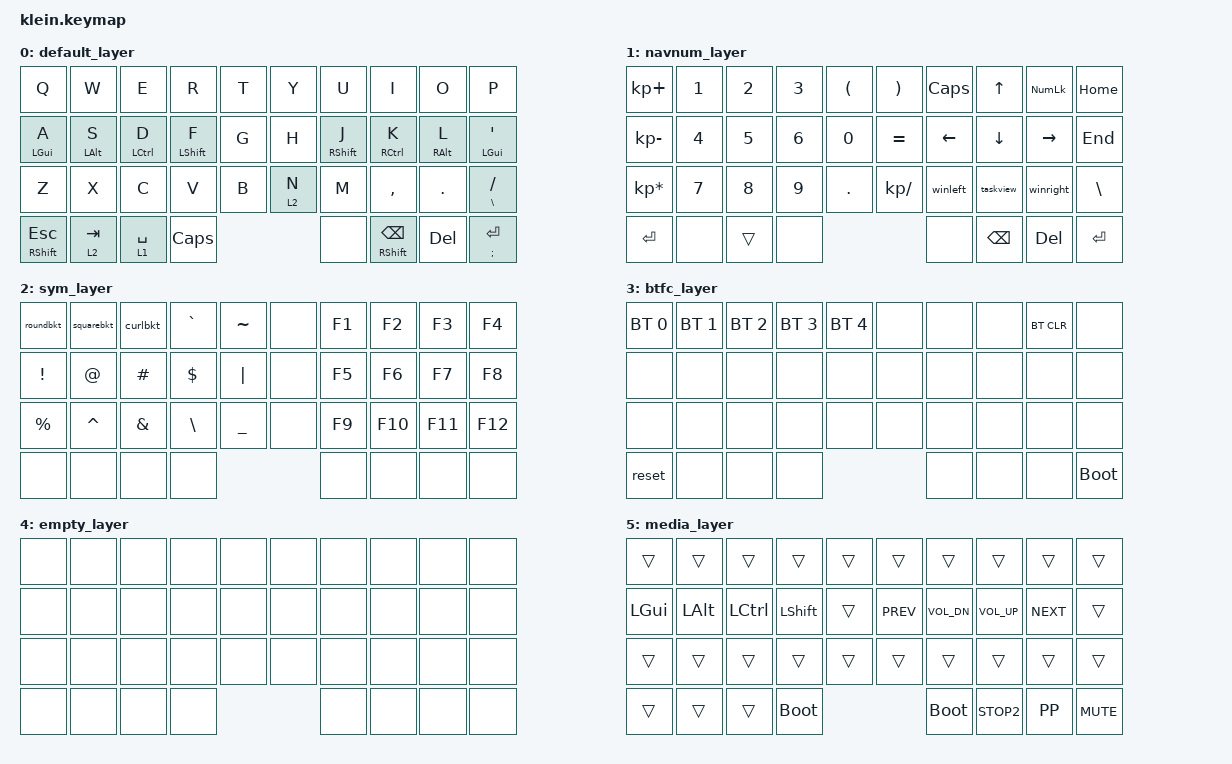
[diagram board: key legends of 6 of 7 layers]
/*
 * Copyright (c) 2020 The ZMK Contributors
 *
 * SPDX-License-Identifier: MIT
 */

#define ZMK_POINTING_DEFAULT_MOVE_VAL 1500  // default: 600
#define ZMK_POINTING_DEFAULT_SCRL_VAL 20    // default: 10
#define BASE 0
#define NAV  1
#define SYM  2
#define BTC  3
#define NON  4
#define MEDIA  5
#define BLU 6

#include <behaviors.dtsi> 
#include <dt-bindings/zmk/keys.h>
#include <dt-bindings/zmk/bt.h>
#include <dt-bindings/zmk/outputs.h>
#include <dt-bindings/zmk/pointing.h>


/ {

behaviors {

      macros {
         roundbkt: round_brackets {
            label= "round_brackets";
            compatible = "zmk,behavior-macro";
            #binding-cells = <0>; 
            bindings
                = <&macro_tap &kp LPAR &kp RPAR>;
         };
         
         
         squarebkt: square_brackets {
            label= "square_brackets";
            compatible = "zmk,behavior-macro";
            #binding-cells = <0>;
            bindings
                = <&macro_tap &kp LBKT &kp RBKT>;
         };
         
         
         curlbkt: curl_brackets {
            label= "curl_brackets";
            compatible = "zmk,behavior-macro";
            #binding-cells = <0>;
            bindings
                = <&macro_tap &kp LBRC &kp RBRC>;
         };
        
         apostrophe: apostrophe {
            label= "apostrophe";
            compatible = "zmk,behavior-macro";
            #binding-cells = <0>;
            bindings
                = <&macro_tap &kp DQT &kp DQT>;
         };
        
         winleft: winleft {
            label= "winleft";
            compatible = "zmk,behavior-macro";
            #binding-cells = <0>;
            bindings
                = <&macro_press &kp LGUI &kp LCTRL>, 
                <&macro_tap &kp LEFT>,
                <&macro_release &kp LGUI &kp LCTRL>;
         };
        
         winright: winright {
            label= "winright";
            compatible = "zmk,behavior-macro";
            #binding-cells = <0>;
            bindings
                = <&macro_press &kp LGUI &kp LCTRL>, 
                <&macro_tap &kp RIGHT>,
                <&macro_release &kp LGUI &kp LCTRL>;
         };
        
         taskview: taskview {
            label= "taskview";
            compatible = "zmk,behavior-macro";
            #binding-cells = <0>;
            bindings
                = <&macro_press &kp LGUI>, 
                <&macro_tap &kp TAB>,
                <&macro_release &kp LGUI>;
         };
      };
    
      hm: homerow_mods {
        compatible = "zmk,behavior-hold-tap";
        label = "HOMEROW_MODS";
        #binding-cells = <2>;
        tapping_term_ms = <150>;
        flavor = "tap-preferred";
        bindings = <&kp>, <&kp>;
    };
    
      te: tab_enter {
        compatible = "zmk,behavior-hold-tap";
        label = "TAB_ENTER";
        #binding-cells = <2>;
        tapping_term_ms = <50>;
        flavor = "tap-preferred";
        bindings = <&kp>, <&kp>;
    };
    
    td_mt_enter_tab_f2_f4: tap_dance_mod_tap_tab_esc {
            compatible = "zmk,behavior-tap-dance";
            label = "TAP_DANCE_MOD_TAP_enter_tab_f2_f4";
            #binding-cells = <0>;
            tapping-term-ms = <200>;
            bindings = <&te TAB ENTER>, <&kp F2>, <&kp F4>;
        };

    combos {
    compatible = "zmk,combos";
    combo_layer3 {
            timeout-ms = <50>;
            key-positions = <32 35>;
            bindings = <&mo 3>;
       };
    };
  };
};

/ {
    keymap {
        compatible = "zmk,keymap";

        default_layer {
//          ------------------------------------------------------------------------------------------------------------
//          |  Q  |  W  |  E   |  R       |  T   |                                           |  Y   |  U    |  I    |  O   |   P   |
//          |  A  |  S  |  D   |  F       |  G   |                                           |  H   |  J    |  K    |  L   |   '   |
//          |  Z  |  X  |  C   |  V       |  B   |                                           |  N   |  M    |  ,    |  .   |   /   |
//                      | ESC  | lyr2/TAB |  TAB | BOOTLOADER |                         | MUTE | RET | BKSP | DEL |

            bindings = <
&kp Q          &kp W          &kp E          &kp R          &kp T               &kp Y          &kp U          &kp I          &kp O          &kp P
&hm LGUI A     &hm LALT S     &hm LCTRL D    &hm LSHFT F    &kp G               &kp H          &hm RSHFT J    &hm RCTRL K    &hm RALT L     &hm LGUI SQT
&kp Z          &kp X          &kp C          &kp V          &kp B               &lt 2 N        &kp M          &kp COMMA      &kp DOT        &hm BSLH FSLH
&hm RSHFT ESC  &lt 2 TAB      &lt 1 SPACE    &kp CAPS                                          &none          &hm RSHFT BSPC &kp DEL        &hm SEMI ENTER
            >;
        sensor-bindings = <&inc_dec_msc SCRL_UP SCRL_DOWN &inc_dec_msc SCRL_LEFT SCRL_RIGHT>;
        };

        navnum_layer {

            bindings = <
&kp KP_PLUS     &kp N1         &kp N2         &kp N3         &kp LPAR            &kp RPAR       &kp CAPS       &kp UP         &kp KP_NUMLOCK &kp HOME
&kp KP_MINUS    &kp N4         &kp N5         &kp N6         &kp N0              &kp EQUAL      &kp LEFT       &kp DOWN       &kp RIGHT      &kp END
&kp KP_MULTIPLY &kp N7         &kp N8         &kp N9         &kp DOT             &kp KP_DIVIDE  &winleft       &taskview      &winright      &kp BSLH
&kp ENTER       &none          &trans         &none                                             &none          &kp BSPC       &kp DEL        &kp ENTER
            >;
        sensor-bindings = <&inc_dec_kp PG_UP PG_DN &inc_dec_kp HOME END>;
        };

        sym_layer {
            
            bindings = <
&roundbkt      &squarebkt     &curlbkt       &kp GRAVE      &kp TILDE           &none          &kp F1         &kp F2         &kp F3         &kp F4
&kp EXCL       &kp AT         &kp HASH       &kp DOLLAR     &kp PIPE            &none          &kp F5         &kp F6         &kp F7         &kp F8
&kp PRCNT      &kp CARET      &kp AMPERSAND  &kp BACKSLASH  &kp UNDERSCORE      &none          &kp F9         &kp F10        &kp F11        &kp F12
&none          &none          &none          &none                                             &none          &none          &none          &none
            >;
        sensor-bindings = <&inc_dec_kp C_VOL_DN C_VOL_UP>;
        };

        btfc_layer {
            
            bindings = <
&bt BT_SEL 0   &bt BT_SEL 1   &bt BT_SEL 2   &bt BT_SEL 3   &bt BT_SEL 4        &none          &none          &none          &bt BT_CLR     &none 
&none          &none          &none          &none          &none               &none          &none          &none          &none          &none 
&none          &none          &none          &none          &none               &none          &none          &none          &none          &none 
&reset         &none          &none          &none                                             &none          &none          &none          &bootloader 
            >;
        sensor-bindings = <&inc_dec_kp C_BRI_UP C_BRI_DN &inc_dec_kp C_VOL_DN C_VOL_UP>;
        };

        empty_layer {
            
            bindings = <
&none       &none       &none       &none       &none              &none       &none       &none       &none       &none
&none       &none       &none       &none       &none              &none       &none       &none       &none       &none
&none       &none       &none       &none       &none              &none       &none       &none       &none       &none
&none       &none       &none       &none                                      &none       &none       &none       &none
            >;
        sensor-bindings = <&inc_dec_kp C_VOL_DN C_VOL_UP>;
        };

        media_layer {
            
            bindings = <
&trans         &trans         &trans         &trans         &trans              &trans         &trans         &trans         &trans         &trans
&kp LGUI       &kp LALT       &kp LCTRL      &kp LSHFT      &trans              &kp K_PREV     &kp K_VOL_DN   &kp K_VOL_UP   &kp K_NEXT     &trans
&trans         &trans         &trans         &trans         &trans              &trans         &trans         &trans         &trans         &trans
&trans         &trans         &trans         &bootloader                                       &bootloader    &kp K_STOP2    &kp K_PP       &kp K_MUTE
            >;
        sensor-bindings = <&inc_dec_kp C_VOL_DN C_VOL_UP>;
        };

        blu_layer {
            
            bindings = <
&trans         &trans         &trans         &trans         &trans              &bt BT_CLR     &trans         &trans         &trans         &trans
&trans         &bt BT_SEL 3   &bt BT_SEL 4   &trans         &trans              &trans         &bt BT_PRV     &bt BT_NXT     &trans         &trans
&trans         &bt BT_SEL 0   &bt BT_SEL 1   &bt BT_SEL 2   &trans              &trans         &trans         &trans         &trans         &trans
&trans         &trans         &trans         &trans         &trans                             &trans         &trans         &trans         &trans
            >;
        sensor-bindings = <&inc_dec_kp C_VOL_DN C_VOL_UP>;
        };
    };
};
 
 
